# ECC_AGGR_ECC_AGGR_3F013000h register map
Vendor: Texas Instruments
Peripheral module from a debugger description file (folder AM275x).
Registers are 32-bit, access not given, reset 0x0 unless marked. A register's access mark holds for its fields unless they carry their own. Offsets are as the file gives them; lines under a group give offsets from that group; [hi:lo] are bit positions; {n}, {i} and the like mark numbered series; 'fields as' and 'values as' point back to an identical list; <NAME> marks a mode.

## ecc_aggr
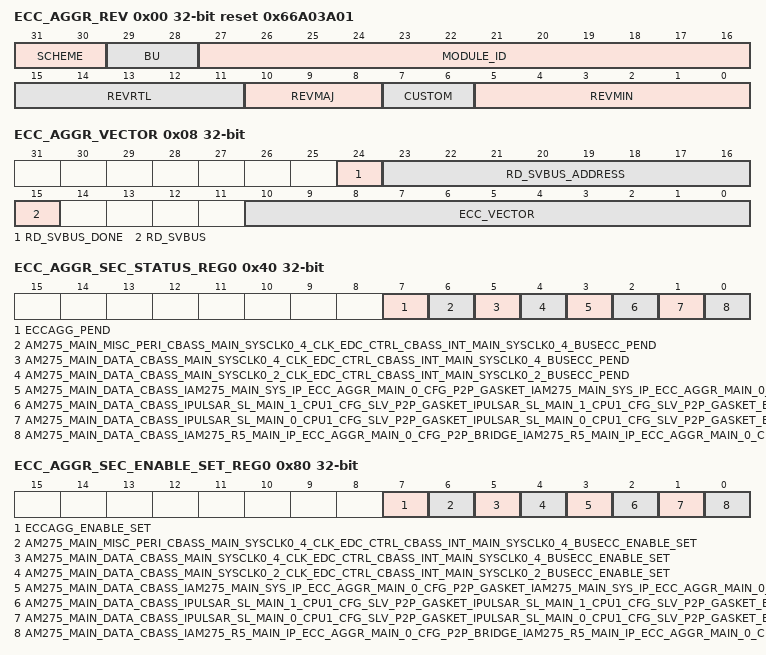
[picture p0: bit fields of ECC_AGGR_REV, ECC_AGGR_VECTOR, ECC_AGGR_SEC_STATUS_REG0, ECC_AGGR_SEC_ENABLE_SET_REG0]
0x00 ECC_AGGR_REV ro reset 0x66A03A01 — Revision parameters
  [31:30] SCHEME
  [29:28] BU — Business Unit
  [27:16] MODULE_ID
  [15:11] REVRTL — RTL version
  [10:8] REVMAJ — Major version
  [7:6] CUSTOM — Custom version
  [5:0] REVMIN — Minor version
0x08 ECC_AGGR_VECTOR — ECC Vector Register
  [24] RD_SVBUS_DONE — Status to indicate if read on serial VBUS is complete, write of any value will clear this bit. (access R/W1TC)
  [23:16] RD_SVBUS_ADDRESS rw — Read address
  [15] RD_SVBUS — Write 1 to trigger a read on the serial VBUS (access R/W1TS)
  [10:0] ECC_VECTOR rw — Value written to select the corresponding ECC RAM for control or status
0x0C ECC_AGGR_STAT ro reset 0x8 — Misc Status
  [10:0] NUM_RAMS — Indicates the number of RAMS serviced by the ECC aggregator
0x10 ECC_AGGR_RESERVED_SVBUS_j rw — Reference other documents that contain the ECC RAM wrapper and EDC controller serial vbus register sets.
  [31:0] DATA — Serial VBUS register data
0x3C ECC_AGGR_SEC_EOI_REG — EOI Register
  [0] EOI_WR — EOI Register (access R/W1TS)
0x40 ECC_AGGR_SEC_STATUS_REG0 — Interrupt Status Register 0
  [7] ECCAGG_PEND — Interrupt Pending Status for eccagg_pend (access R/W1TS)
  [6] AM275_MAIN_MISC_PERI_CBASS_MAIN_SYSCLK0_4_CLK_EDC_CTRL_CBASS_INT_MAIN_SYSCLK0_4_BUSECC_PEND — Interrupt Pending Status for am275_main_misc_peri_cbass_main_SYSCLK0_4_clk_edc_ctrl_cbass_int_main_SYSCLK0_4_busecc_pend (access R/W1TS)
  [5] AM275_MAIN_DATA_CBASS_MAIN_SYSCLK0_4_CLK_EDC_CTRL_CBASS_INT_MAIN_SYSCLK0_4_BUSECC_PEND — Interrupt Pending Status for am275_main_data_cbass_main_SYSCLK0_4_clk_edc_ctrl_cbass_int_main_SYSCLK0_4_busecc_pend (access R/W1TS)
  [4] AM275_MAIN_DATA_CBASS_MAIN_SYSCLK0_2_CLK_EDC_CTRL_CBASS_INT_MAIN_SYSCLK0_2_BUSECC_PEND — Interrupt Pending Status for am275_main_data_cbass_main_SYSCLK0_2_clk_edc_ctrl_cbass_int_main_SYSCLK0_2_busecc_pend (access R/W1TS)
  [3] AM275_MAIN_DATA_CBASS_IAM275_MAIN_SYS_IP_ECC_AGGR_MAIN_0_CFG_P2P_GASKET_IAM275_MAIN_SYS_IP_ECC_AGGR_MAIN_0_CFG_P2P_GASKET_BUSECC_PEND — Interrupt Pending Status for am275_main_data_cbass_Iam275_main_sys_ip_ecc_aggr_main_0_cfg_p2p_gasket_Iam275_main_sys_ip_ecc_aggr_main_0_cfg_p2p_gasket_busecc_pend (access R/W1TS)
  [2] AM275_MAIN_DATA_CBASS_IPULSAR_SL_MAIN_1_CPU1_CFG_SLV_P2P_GASKET_IPULSAR_SL_MAIN_1_CPU1_CFG_SLV_P2P_GASKET_BUSECC_PEND — Interrupt Pending Status for am275_main_data_cbass_Ipulsar_sl_main_1_cpu1_cfg_slv_p2p_gasket_Ipulsar_sl_main_1_cpu1_cfg_slv_p2p_gasket_busecc_pend (access R/W1TS)
  [1] AM275_MAIN_DATA_CBASS_IPULSAR_SL_MAIN_0_CPU1_CFG_SLV_P2P_GASKET_IPULSAR_SL_MAIN_0_CPU1_CFG_SLV_P2P_GASKET_BUSECC_PEND — Interrupt Pending Status for am275_main_data_cbass_Ipulsar_sl_main_0_cpu1_cfg_slv_p2p_gasket_Ipulsar_sl_main_0_cpu1_cfg_slv_p2p_gasket_busecc_pend (access R/W1TS)
  [0] AM275_MAIN_DATA_CBASS_IAM275_R5_MAIN_IP_ECC_AGGR_MAIN_0_CFG_P2P_BRIDGE_IAM275_R5_MAIN_IP_ECC_AGGR_MAIN_0_CFG_BRIDGE_SRC_BUSECC_PEND — Interrupt Pending Status for am275_main_data_cbass_Iam275_r5_main_ip_ecc_aggr_main_0_cfg_p2p_bridge_Iam275_r5_main_ip_ecc_aggr_main_0_cfg_bridge_src_busecc_pend (access R/W1TS)
0x80 ECC_AGGR_SEC_ENABLE_SET_REG0 — Interrupt Enable Set Register 0
  [7] ECCAGG_ENABLE_SET — Interrupt Enable Set Register for eccagg_pend (access R/W1TS)
  [6] AM275_MAIN_MISC_PERI_CBASS_MAIN_SYSCLK0_4_CLK_EDC_CTRL_CBASS_INT_MAIN_SYSCLK0_4_BUSECC_ENABLE_SET — Interrupt Enable Set Register for am275_main_misc_peri_cbass_main_SYSCLK0_4_clk_edc_ctrl_cbass_int_main_SYSCLK0_4_busecc_pend (access R/W1TS)
  [5] AM275_MAIN_DATA_CBASS_MAIN_SYSCLK0_4_CLK_EDC_CTRL_CBASS_INT_MAIN_SYSCLK0_4_BUSECC_ENABLE_SET — Interrupt Enable Set Register for am275_main_data_cbass_main_SYSCLK0_4_clk_edc_ctrl_cbass_int_main_SYSCLK0_4_busecc_pend (access R/W1TS)
  [4] AM275_MAIN_DATA_CBASS_MAIN_SYSCLK0_2_CLK_EDC_CTRL_CBASS_INT_MAIN_SYSCLK0_2_BUSECC_ENABLE_SET — Interrupt Enable Set Register for am275_main_data_cbass_main_SYSCLK0_2_clk_edc_ctrl_cbass_int_main_SYSCLK0_2_busecc_pend (access R/W1TS)
  [3] AM275_MAIN_DATA_CBASS_IAM275_MAIN_SYS_IP_ECC_AGGR_MAIN_0_CFG_P2P_GASKET_IAM275_MAIN_SYS_IP_ECC_AGGR_MAIN_0_CFG_P2P_GASKET_BUSECC_ENABLE_SET — Interrupt Enable Set Register for am275_main_data_cbass_Iam275_main_sys_ip_ecc_aggr_main_0_cfg_p2p_gasket_Iam275_main_sys_ip_ecc_aggr_main_0_cfg_p2p_gasket_busecc_pend (access R/W1TS)
  [2] AM275_MAIN_DATA_CBASS_IPULSAR_SL_MAIN_1_CPU1_CFG_SLV_P2P_GASKET_IPULSAR_SL_MAIN_1_CPU1_CFG_SLV_P2P_GASKET_BUSECC_ENABLE_SET — Interrupt Enable Set Register for am275_main_data_cbass_Ipulsar_sl_main_1_cpu1_cfg_slv_p2p_gasket_Ipulsar_sl_main_1_cpu1_cfg_slv_p2p_gasket_busecc_pend (access R/W1TS)
  [1] AM275_MAIN_DATA_CBASS_IPULSAR_SL_MAIN_0_CPU1_CFG_SLV_P2P_GASKET_IPULSAR_SL_MAIN_0_CPU1_CFG_SLV_P2P_GASKET_BUSECC_ENABLE_SET — Interrupt Enable Set Register for am275_main_data_cbass_Ipulsar_sl_main_0_cpu1_cfg_slv_p2p_gasket_Ipulsar_sl_main_0_cpu1_cfg_slv_p2p_gasket_busecc_pend (access R/W1TS)
  [0] AM275_MAIN_DATA_CBASS_IAM275_R5_MAIN_IP_ECC_AGGR_MAIN_0_CFG_P2P_BRIDGE_IAM275_R5_MAIN_IP_ECC_AGGR_MAIN_0_CFG_BRIDGE_SRC_BUSECC_ENABLE_SET — Interrupt Enable Set Register for am275_main_data_cbass_Iam275_r5_main_ip_ecc_aggr_main_0_cfg_p2p_bridge_Iam275_r5_main_ip_ecc_aggr_main_0_cfg_bridge_src_busecc_pend (access R/W1TS)
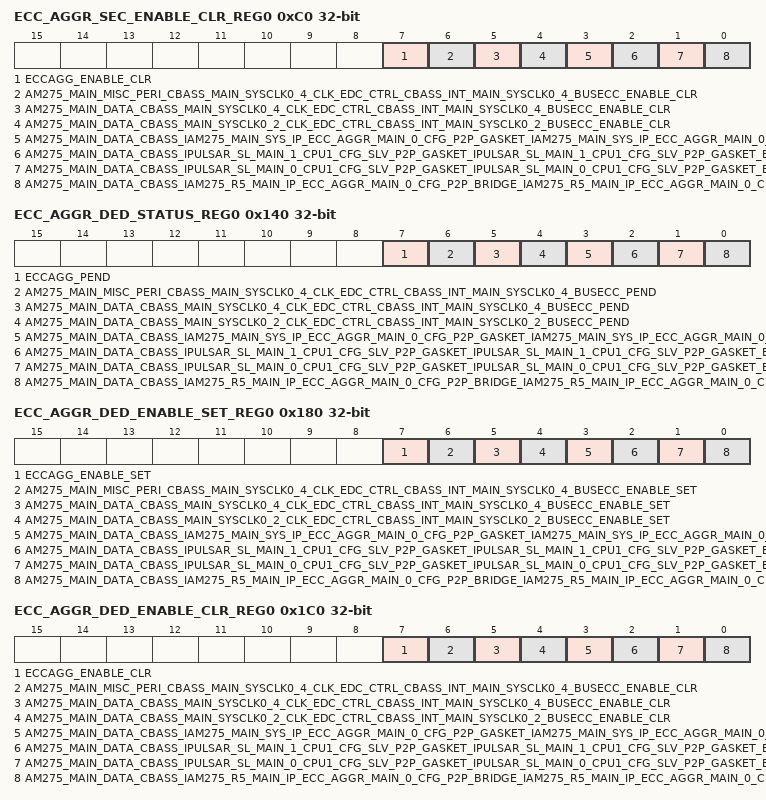
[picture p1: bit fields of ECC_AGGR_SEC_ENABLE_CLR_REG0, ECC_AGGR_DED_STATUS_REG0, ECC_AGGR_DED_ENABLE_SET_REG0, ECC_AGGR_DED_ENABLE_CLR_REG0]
0xC0 ECC_AGGR_SEC_ENABLE_CLR_REG0 — Interrupt Enable Clear Register 0
  [7] ECCAGG_ENABLE_CLR — Interrupt Enable Clear Register for eccagg_pend (access R/W1TC)
  [6] AM275_MAIN_MISC_PERI_CBASS_MAIN_SYSCLK0_4_CLK_EDC_CTRL_CBASS_INT_MAIN_SYSCLK0_4_BUSECC_ENABLE_CLR — Interrupt Enable Clear Register for am275_main_misc_peri_cbass_main_SYSCLK0_4_clk_edc_ctrl_cbass_int_main_SYSCLK0_4_busecc_pend (access R/W1TC)
  [5] AM275_MAIN_DATA_CBASS_MAIN_SYSCLK0_4_CLK_EDC_CTRL_CBASS_INT_MAIN_SYSCLK0_4_BUSECC_ENABLE_CLR — Interrupt Enable Clear Register for am275_main_data_cbass_main_SYSCLK0_4_clk_edc_ctrl_cbass_int_main_SYSCLK0_4_busecc_pend (access R/W1TC)
  [4] AM275_MAIN_DATA_CBASS_MAIN_SYSCLK0_2_CLK_EDC_CTRL_CBASS_INT_MAIN_SYSCLK0_2_BUSECC_ENABLE_CLR — Interrupt Enable Clear Register for am275_main_data_cbass_main_SYSCLK0_2_clk_edc_ctrl_cbass_int_main_SYSCLK0_2_busecc_pend (access R/W1TC)
  [3] AM275_MAIN_DATA_CBASS_IAM275_MAIN_SYS_IP_ECC_AGGR_MAIN_0_CFG_P2P_GASKET_IAM275_MAIN_SYS_IP_ECC_AGGR_MAIN_0_CFG_P2P_GASKET_BUSECC_ENABLE_CLR — Interrupt Enable Clear Register for am275_main_data_cbass_Iam275_main_sys_ip_ecc_aggr_main_0_cfg_p2p_gasket_Iam275_main_sys_ip_ecc_aggr_main_0_cfg_p2p_gasket_busecc_pend (access R/W1TC)
  [2] AM275_MAIN_DATA_CBASS_IPULSAR_SL_MAIN_1_CPU1_CFG_SLV_P2P_GASKET_IPULSAR_SL_MAIN_1_CPU1_CFG_SLV_P2P_GASKET_BUSECC_ENABLE_CLR — Interrupt Enable Clear Register for am275_main_data_cbass_Ipulsar_sl_main_1_cpu1_cfg_slv_p2p_gasket_Ipulsar_sl_main_1_cpu1_cfg_slv_p2p_gasket_busecc_pend (access R/W1TC)
  [1] AM275_MAIN_DATA_CBASS_IPULSAR_SL_MAIN_0_CPU1_CFG_SLV_P2P_GASKET_IPULSAR_SL_MAIN_0_CPU1_CFG_SLV_P2P_GASKET_BUSECC_ENABLE_CLR — Interrupt Enable Clear Register for am275_main_data_cbass_Ipulsar_sl_main_0_cpu1_cfg_slv_p2p_gasket_Ipulsar_sl_main_0_cpu1_cfg_slv_p2p_gasket_busecc_pend (access R/W1TC)
  [0] AM275_MAIN_DATA_CBASS_IAM275_R5_MAIN_IP_ECC_AGGR_MAIN_0_CFG_P2P_BRIDGE_IAM275_R5_MAIN_IP_ECC_AGGR_MAIN_0_CFG_BRIDGE_SRC_BUSECC_ENABLE_CLR — Interrupt Enable Clear Register for am275_main_data_cbass_Iam275_r5_main_ip_ecc_aggr_main_0_cfg_p2p_bridge_Iam275_r5_main_ip_ecc_aggr_main_0_cfg_bridge_src_busecc_pend (access R/W1TC)
0x13C ECC_AGGR_DED_EOI_REG — EOI Register
  [0] EOI_WR — EOI Register (access R/W1TS)
0x140 ECC_AGGR_DED_STATUS_REG0 — Interrupt Status Register 0
  fields as ECC_AGGR_SEC_STATUS_REG0
0x180 ECC_AGGR_DED_ENABLE_SET_REG0 — Interrupt Enable Set Register 0
  fields as ECC_AGGR_SEC_ENABLE_SET_REG0
0x1C0 ECC_AGGR_DED_ENABLE_CLR_REG0 — Interrupt Enable Clear Register 0
  fields as ECC_AGGR_SEC_ENABLE_CLR_REG0
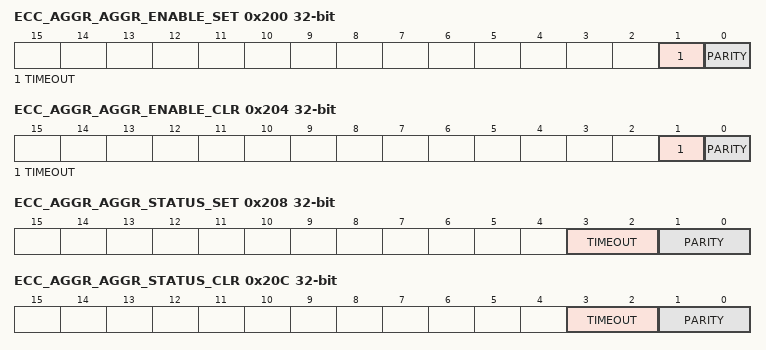
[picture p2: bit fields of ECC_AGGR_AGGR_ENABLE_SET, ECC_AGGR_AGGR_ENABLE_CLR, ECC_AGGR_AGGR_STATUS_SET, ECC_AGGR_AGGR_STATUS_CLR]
0x200 ECC_AGGR_AGGR_ENABLE_SET — AGGR interrupt enable set Register
  [1] TIMEOUT — interrupt enable set for svbus timeout errors (access R/W1TS)
  [0] PARITY — interrupt enable set for parity errors (access R/W1TS)
0x204 ECC_AGGR_AGGR_ENABLE_CLR — AGGR interrupt enable clear Register
  [1] TIMEOUT — interrupt enable clear for svbus timeout errors (access R/W1TC)
  [0] PARITY — interrupt enable clear for parity errors (access R/W1TC)
0x208 ECC_AGGR_AGGR_STATUS_SET — AGGR interrupt status set Register
  [3:2] TIMEOUT — interrupt status set for svbus timeout errors (access R/WI)
  [1:0] PARITY — interrupt status set for parity errors (access R/WI)
0x20C ECC_AGGR_AGGR_STATUS_CLR — AGGR interrupt status clear Register
  [3:2] TIMEOUT — interrupt status clear for svbus timeout errors (access R/WD)
  [1:0] PARITY — interrupt status clear for parity errors (access R/WD)
